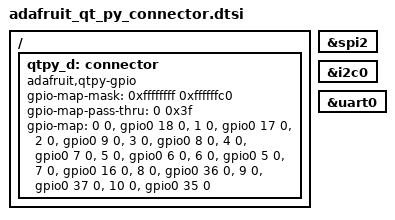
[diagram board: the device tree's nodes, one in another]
/ {
	qtpy_d: connector {
		compatible = "adafruit,qtpy-gpio";
		#gpio-cells = <2>;
		gpio-map-mask = <0xffffffff 0xffffffc0>;
		gpio-map-pass-thru = <0 0x3f>;
		gpio-map = <0 0 &gpio0 18 0>,	/* D0 / A0 */
			   <1 0 &gpio0 17 0>,	/* D1 / A1 */
			   <2 0 &gpio0 9 0>,	/* D2 / A2 */
			   <3 0 &gpio0 8 0>,	/* D3 / A3 */
			   <4 0 &gpio0 7 0>,	/* D4 / SDA */
			   <5 0 &gpio0 6 0>,	/* D5 / SCL */
			   <6 0 &gpio0 5 0>,	/* D6 / TX */
			   <7 0 &gpio0 16 0>,	/* D7 / RX */
			   <8 0 &gpio0 36 0>,	/* D8 / SCK */
			   <9 0 &gpio0 37 0>,	/* D9 / MISO */
			   <10 0 &gpio0 35 0>;	/* D10 / MOSI */
	};
};

qtpy_spi: &spi2 {};
qtpy_i2c: &i2c0 {};
qtpy_serial: &uart0 {};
